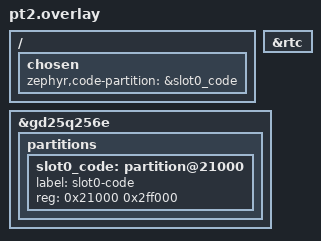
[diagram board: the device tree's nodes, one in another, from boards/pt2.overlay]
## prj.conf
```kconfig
CONFIG_ASSERT=y
CONFIG_BOOT_BANNER=n
CONFIG_CONSOLE=y
CONFIG_CRC=y
CONFIG_DISPLAY=y
CONFIG_FLASH=y
CONFIG_HEAP_MEM_POOL_SIZE=65536
CONFIG_MAIN_STACK_SIZE=2048
CONFIG_MINIMAL_LIBC_RAND=y
# NimBLE's GATT server registers services via libc realloc/malloc
# (ble_gatts_add_svcs). Without a real malloc arena those return NULL and
# ble_svc_gap_init panics. Match the standalone ble app's allocator.
CONFIG_COMMON_LIBC_MALLOC=y
CONFIG_COMMON_LIBC_MALLOC_ARENA_SIZE=16384
CONFIG_NUM_PREEMPT_PRIORITIES=12
CONFIG_PRINTK=y
CONFIG_RTC=y
CONFIG_REBOOT=y
CONFIG_SERIAL=y
CONFIG_THREAD_NAME=y
CONFIG_UART_CONSOLE=y

CONFIG_SYSTEM_WORKQUEUE_STACK_SIZE=4096

# PebbleOS emits concise bring-up markers directly on UART.
CONFIG_LOG=y
CONFIG_LOG_MODE_IMMEDIATE=y

# Keep firmware threads privileged. The custom hooks only alter the app map
# after fw_sandbox_launch() has prepared and armed the sandbox.
CONFIG_ARM_MPU=y
CONFIG_ARM_CUSTOM_SVC_HOOK=y
CONFIG_ARM_CUSTOM_THREAD_RESTORE_HOOK=y
CONFIG_USERSPACE=n
```

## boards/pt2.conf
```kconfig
CONFIG_GPIO=y
CONFIG_SF32LB_JDI=y
CONFIG_WATCHDOG=y

# NimBLE host and the SF32 LCPU controller transport.
CONFIG_USE_SIFLI_HAL=y
CONFIG_USE_SIFLI_HAL_AON=y
CONFIG_USE_SIFLI_HAL_LCPU_PATCH=y
CONFIG_USE_SIFLI_HAL_MAILBOX=y
CONFIG_USE_SIFLI_HAL_SYSTEM_CONFIG=y

# HCPU/LCPU HCI rings live in shared SRAM. The port does not yet install the
# shipping non-cacheable MPU region, so keep the HCPU D-cache disabled to make
# controller IPC coherent.
CONFIG_DCACHE=n
```

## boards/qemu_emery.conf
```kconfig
CONFIG_INPUT=y
CONFIG_FLASH_PAGE_LAYOUT=y
# RTC_TICKS_HZ derives from this; the animation rate-control loop needs ~1ms
# resolution (shipping runs 1024 Hz) or frame cadence oscillates.
CONFIG_SYS_CLOCK_TICKS_PER_SEC=1000
```

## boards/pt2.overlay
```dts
/* SPDX-License-Identifier: Apache-2.0 */

&rtc {
	status = "okay";
};

/* Slot 0 base 0x12020000. pblboot's 28-byte header sits at the base and the
 * firmware body (vector table) begins at slot_base + 0x1000, matching pblboot
 * CONFIG_FIRMWARE_OFFSET=4096. Reserve that 0x1000 header page outside ROM. */
&gd25q256e {
	partitions {
		/delete-node/ partition@10000;

		slot0_code: partition@21000 {
			label = "slot0-code";
			reg = <0x21000 0x2ff000>;
		};
	};
};

/ {
	chosen {
		zephyr,code-partition = &slot0_code;
	};
};
```

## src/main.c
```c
/* SPDX-FileCopyrightText: 2024 Google LLC */
/* SPDX-License-Identifier: Apache-2.0 */

#include <time.h>

#include "FreeRTOS.h"
#include "app_registry.h"
#include "applib/tick_timer_service.h"
#include "applib/ui/animation_private.h"
#include "applib/tick_timer_service_private.h"
#include "ble_comm.h"
#include "button_input.h"
#include "fw_ota_boot.h"
#include "kernel/event_loop.h"
#include "kernel/events.h"
#include "kernel/kernel_applib_state.h"
#include "process_state/app_state/app_state.h"
#include "kernel/pebble_tasks.h"
#include "kernel/util/task_init.h"
#include "launcher_ui.h"
#include "pbl/drivers/task_watchdog.h"
#include "pbl/logging/logging.h"
#include "pbl/services/analytics/analytics.h"
#include "pbl/services/event_service.h"
#include "pbl/services/new_timer/new_timer.h"
#include "pbl/services/new_timer/new_timer_service.h"
#include "pbl/services/regular_timer.h"
#include "pbl/services/system_task.h"
#include "pfs_boot.h"
#include "sandbox_launcher.h"

void board_early_init(void);
void board_init(void);

static TimerID s_probe_timer;

static void prv_watchdog_timer_callback(void *data) {
  (void)data;
  task_watchdog_bit_set(PebbleTask_NewTimers);
}

static RegularTimerInfo s_watchdog_timer = {
    .cb = prv_watchdog_timer_callback,
};

static void prv_timer_dispatched(void *data) {
  (void)data;
  PBL_LOG_ALWAYS("FW_TIMER dispatched");
}

static void prv_timer_fired(void *data) {
  (void)data;
  launcher_task_add_callback(prv_timer_dispatched, NULL);
}

static void prv_tick_handler(struct tm *tick_time, TimeUnits units_changed) {
  (void)units_changed;
  PBL_LOG_ALWAYS("FW_TICK %02d:%02d:%02d", tick_time->tm_hour, tick_time->tm_min,
                 tick_time->tm_sec);
}

// Shipping drives tick_timer_service from a RegularTimer that the port never
// pumps, so the clock and music progress never advanced. Emit PEBBLE_TICK_EVENT
// once a second from a repeating new_timer (which the port does pump); the
// per-task tick_timer_service state turns it into second/minute tick callbacks.
extern time_t rtc_get_time(void);
static TimerID s_tick_timer;

static void prv_second_tick(void *data) {
  (void)data;
  PebbleEvent e = {
    .type = PEBBLE_TICK_EVENT,
    .clock_tick = { .tick_time = rtc_get_time() },
  };
  event_put(&e);
}

static void prv_kernel_main(void *parameter) {
  (void)parameter;
  task_init();

  // Shipping inits the kernel animation state from kernel_ui_init on
  // KernelMain; both engine states allocate their aux state on the heap.
  animation_private_state_init(kernel_applib_get_animation_state());
  animation_private_state_init(app_state_get_animation_state());

  TickTimerServiceState *tick_state = kernel_applib_get_tick_timer_service_state();
  tick_timer_service_state_init(tick_state);
  tick_timer_service_init();
  tick_timer_service_subscribe(SECOND_UNIT, prv_tick_handler);

  s_probe_timer = new_timer_create();
  new_timer_start(s_probe_timer, 1500, prv_timer_fired, NULL, 0);

  s_tick_timer = new_timer_create();
  new_timer_start(s_tick_timer, 1000, prv_second_tick, NULL, TIMER_START_FLAG_REPEATING);

  PBL_LOG_ALWAYS("FW_SERVICES_OK");

  // Buttons: prove the debounce filter, then bring up the real click_recognizer
  // and start sampling the physical GPIOs. Must run on KernelMain so click.c's
  // app_timer callbacks dispatch back on this task via the event loop.
  button_input_selfcheck();
  input_service_init();
  button_zephyr_init();

  // PFS must mount and the app registry must enumerate before board drivers,
  // the watchdog, or analytics run. Bringing those up first (as the un-stub
  // originally did) perturbs the system out of the clean state PFS mounts in
  // and the filesystem fails to mount (apps=0). Keep filesystem-first ordering.
  if (fw_pfs_boot() == 0) {
    PBL_LOG_ALWAYS("FW_PFS_UP");
    fw_app_registry_init();
    // Real shell + notification prefs (shipping: shell_event_loop /
    // services init); load and persist their settings files on PFS.
    extern void shell_prefs_init(void);
    shell_prefs_init();
    extern void alerts_preferences_init(void);
    alerts_preferences_init();
    extern void do_not_disturb_init(void);
    do_not_disturb_init();
    // pin_db must be up before alarm_init: reloading persisted alarms re-adds
    // their timeline pins through alarm_pin_add -> pin_db.
    extern void notification_storage_init(void);
    notification_storage_init();
    extern void pin_db_init(void);
    pin_db_init();
    extern void alarm_init(void);
    alarm_init();
    // Shipping enables the alarm service via the services_normal registry, which
    // the port does not compile; without this s_alarms_enabled stays false and a
    // firing alarm never posts PEBBLE_ALARM_CLOCK_EVENT.
    extern void alarm_service_enable_alarms(bool enable);
    alarm_service_enable_alarms(true);
    extern void fw_alarm_alert_init(void);
    fw_alarm_alert_init();
    extern void fw_pbw_install_init(void);
    fw_pbw_install_init();
    extern void persist_service_init(void);
    persist_service_init();
#if defined(CONFIG_BOARD_QEMU_EMERY)
    extern void fw_qemu_notif_rx_init(void);
    fw_qemu_notif_rx_init();
#endif
  }

  // Board drivers / watchdog / analytics: real Zephyr-backed bring-up, after PFS.
  task_watchdog_init();
  task_watchdog_pause(30);
  regular_timer_add_seconds_callback(&s_watchdog_timer);
  pbl_analytics_init();
  PBL_ANALYTICS_SET_UNSIGNED(uptime_s, 0U);
  board_init();

  // Controller calibration and NimBLE host startup run on dedicated Zephyr
  // threads. Keep this after PFS and board initialization so shared-RAM/radio
  // bring-up cannot perturb the clean state required by the filesystem mount.
  fw_ble_init();

  task_watchdog_mask_set(PebbleTask_KernelMain);
  task_watchdog_resume();
  PBL_LOG_ALWAYS("FW_WATCHDOG_OK");
  PBL_LOG_ALWAYS("FW_ANALYTICS_OK");

  // Stand up the real window stack + launcher menu and run the KernelMain UI
  // event loop. Navigation consumes the button/click-service events wired above
  // (button_zephyr -> event queue -> input_service click_recognizer); SELECT
  // launches the selected app. Replaces the previous auto-launch + bare
  // launcher_main_loop().
  fw_launcher_ui_run();
}

static void prv_log_stubs(void) {
  // ponytail: the port writes Pebble framebuffers directly with Zephyr's JDI
  // display driver. Add the real compositor and kernel-ui service graph here.
  PBL_LOG_ALWAYS("FW_STUB display_compositor");
}

int main(void) {
  PBL_LOG_ALWAYS("FW_BOOT");
  board_early_init();
  fw_boot_select_and_report();
  if (fw_ota_test_injection_requested() &&
      (fw_ota_inject_test_image() != 0)) {
    PBL_LOG_ALWAYS("FW_OTA_TEST_FAILED");
  }
  prv_log_stubs();

  events_init();
  event_service_system_init();
  new_timer_service_init();
  regular_timer_init();
  system_task_init();
  // KernelBackground adds itself to the task-watchdog mask but only feeds its
  // bit while running a callback; this registers the per-second idle feed that
  // keeps the HW watchdog fed while KernelBackground sits idle. Without it the
  // masked-but-unfed bit stalls the whole feed and the SoC resets ~10s in.
  system_task_timer_init();

  TaskParameters_t main_task = {
    .pvTaskCode = prv_kernel_main,
    .pcName = "KernelMain",
    .usStackDepth = 10240 / sizeof(portSTACK_TYPE),
    .uxPriority = tskIDLE_PRIORITY + 3,
  };
  pebble_task_create(PebbleTask_KernelMain, &main_task, NULL);
  return 0;
}
```

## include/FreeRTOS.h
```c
/* SPDX-License-Identifier: Apache-2.0 */
#pragma once

#include <stdint.h>

#include <zephyr/kernel.h>

typedef int BaseType_t;
#define portBASE_TYPE int
typedef unsigned int UBaseType_t;
typedef void *QueueHandle_t;
typedef void *QueueSetHandle_t;
typedef void *QueueSetMemberHandle_t;
typedef void *SemaphoreHandle_t;
typedef void *TaskHandle_t;
typedef uint32_t TickType_t;
typedef uint32_t StackType_t;
typedef StackType_t portSTACK_TYPE;

#define pdFALSE 0
#define pdTRUE 1
#define pdFAIL 0
#define pdPASS 1

#define configMAX_PRIORITIES 8
#define configTICK_RATE_HZ CONFIG_SYS_CLOCK_TICKS_PER_SEC
#define portMAX_DELAY UINT32_MAX
#define portPRIVILEGE_BIT 0
#define tskIDLE_PRIORITY 0

typedef struct {
  TaskHandle_t xHandle;
  uint32_t ulRunTimeCounter;
} TaskStatus_t;

typedef enum {
  eRunning,
  eReady,
  eBlocked,
  eSuspended,
  eDeleted,
  eInvalid,
} eTaskState;

typedef struct xMEMORY_REGION {
  void *pvBaseAddress;
  uint32_t ulLengthInBytes;
  uint32_t ulParameters;
} MemoryRegion_t;

#define portNUM_CONFIGURABLE_REGIONS 4

typedef void (*TaskFunction_t)(void *);

typedef struct xTASK_PARAMETERS {
  TaskFunction_t pvTaskCode;
  const char *pcName;
  uint32_t usStackDepth;
  UBaseType_t uxPriority;
  StackType_t *puxStackBuffer;
  MemoryRegion_t xRegions[portNUM_CONFIGURABLE_REGIONS];
  void *pvParameters;
} TaskParameters_t;
```

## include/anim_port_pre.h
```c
/* SPDX-License-Identifier: Apache-2.0 */
#pragma once

// Force-included ahead of the real applib animation engine + animation service
// TUs. Supplies the Zephyr sign_extend dance, FreeRTOS-style critical sections
// (single-pump port: IRQ lock), the legacy2 header's expected types, and the
// scheduler-dump serial sink.
#include "fw_zephyr_pre.h"
#include "port_crit.h"

#include "applib/app_timer.h"

typedef enum AppTaskCtxIdx {
  AppTaskCtxIdxLauncher = 0,
  AppTaskCtxIdxApp,
  AppTaskCtxIdxCount,
} AppTaskCtxIdx;

#include <zephyr/sys/printk.h>
#define dbgserial_putstr_fmt(buffer, size, fmt, ...) \
  do { snprintk((buffer), (size), fmt, ##__VA_ARGS__); printk("%s\n", (buffer)); } while (0)

#include "process_management/process_manager.h"
```

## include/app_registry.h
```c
/* SPDX-License-Identifier: Apache-2.0 */
#pragma once

#include <stdbool.h>
#include <stddef.h>
#include <stdint.h>

#include "process_management/app_install_types.h"
#include "process_management/pebble_process_md.h"
#include "pbl/util/uuid.h"

#define FW_APP_NAME_SIZE 96

typedef struct {
  AppInstallId install_id;
  Uuid uuid;
  uint32_t info_flags;
  bool installed;
  char name[FW_APP_NAME_SIZE + 1];
  // Non-NULL for a privileged built-in system app: its real PebbleProcessMd.
  // The launcher hands this to fw_system_app_launch() on SELECT. NULL entries
  // fall back to the sandboxed PBW launch.
  const PebbleProcessMd *md;
} FwAppRegistryEntry;

void fw_app_registry_init(void);
size_t fw_app_registry_count(void);
const FwAppRegistryEntry *fw_app_registry_get(size_t index);
const FwAppRegistryEntry *fw_launcher_pick_app(void);
const FwAppRegistryEntry *fw_app_registry_find_by_id(AppInstallId install_id);
void fw_app_registry_reload(void);
```

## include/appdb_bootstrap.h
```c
/* SPDX-License-Identifier: Apache-2.0 */
#pragma once

#include "process_management/app_install_types.h"

//! Install the port's bundled test PBW as a normal PFS/AppDB application.
//! Returns INSTALL_ID_INVALID on failure.
AppInstallId fw_appdb_install_test_app(void);
```

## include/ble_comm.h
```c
/* SPDX-License-Identifier: Apache-2.0 */
#pragma once

// Starts controller and NimBLE-host initialization on a dedicated thread.
// The caller must invoke this only after PFS and board initialization.
void fw_ble_init(void);
```

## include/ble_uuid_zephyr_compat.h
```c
/* SPDX-License-Identifier: Apache-2.0 */
#pragma once

// Zephyr exports a four-argument hex2bin. NimBLE has a private, static
// three-argument helper with the same name. Rename only NimBLE's helper.
#include "nimble_zephyr_compat.h"

#define hex2bin nimble_ble_uuid_hex2bin
```

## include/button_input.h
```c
/* SPDX-License-Identifier: Apache-2.0 */
//! Obelix (pt2) button bring-up under Zephyr.
//!
//! Bottom half: reads the four physical button GPIOs, runs the shipping
//! debounce filter, and emits real PebbleEvents (PEBBLE_BUTTON_DOWN/UP).
//! Top half: feeds those events into the real PebbleOS click_recognizer.
#pragma once

#include <stdint.h>

#include "kernel/events.h"
#include <pbl/drivers/button_id.h>

//! Number of stable 2ms samples a button must hold before its state flips.
//! 20 samples * 2ms = 40ms, identical to the shipping sf32lb52 driver.
#define BUTTON_NUM_DEBOUNCE_SAMPLES 20

//! Pure debounce filter state (one per button set). Host-testable: no I/O.
typedef struct {
  uint32_t timers[NUM_BUTTONS];
  uint32_t debounced_state;  //!< bitset, bit i == BUTTON_ID_i currently pressed
} ButtonDebouncer;

//! Advance the debounce filter one 2ms sample.
//! @param raw_state bitset of raw (already active-level-adjusted) pressed bits
//! @return bitset of buttons whose debounced state flipped this step
uint32_t button_debounce_step(ButtonDebouncer *d, uint32_t raw_state);

//! Board backend: prepare the raw button source. Returns 0 on success.
int button_raw_init(void);

//! Board backend: current raw pressed-bitset (active-level adjusted).
uint32_t button_raw_read(void);

//! Bring up the raw button source and start the 2ms sampling timer.
void button_zephyr_init(void);

//! Runtime self-check of the debounce filter + event mapping. Asserts on
//! failure, logs a marker on success. Safe to call once at boot.
void button_input_selfcheck(void);

//! Initialise the click_recognizer demo (owns a ClickManager, subscribes
//! single/repeat/long/multi/raw handlers that log over UART).
void input_service_init(void);

//! Feed one debounced button event into the click_recognizer. Called from the
//! KernelMain event loop. Logs "BTN <id> DOWN/UP".
void input_service_handle_button_event(PebbleEvent *e);
```

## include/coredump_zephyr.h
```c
/* SPDX-License-Identifier: Apache-2.0 */

#pragma once

#include <stdbool.h>

#include <zephyr/arch/cpu.h>
#include <zephyr/toolchain.h>

//! Emit an unread PebbleOS coredump as hex-framed UART records.
//! Returns true when any valid coredump is present, including an already-read one.
bool coredump_zephyr_emit_uart(void);

//! Deliberately generate a CPU fault when PEBBLE_COREDUMP_TEST_FAULT is enabled.
void coredump_zephyr_test_fault(void);

//! Capture the supplied Zephyr fatal frame with the PebbleOS writer and reset.
FUNC_NORETURN void coredump_zephyr_capture_fatal(
    unsigned int reason, const struct arch_esf *esf);
```

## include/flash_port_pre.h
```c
/* SPDX-License-Identifier: Apache-2.0 */
#pragma once

// Force-included (via CMake -include) ahead of the shipping QSPI flash sources
// (src/fw/drivers/flash/gd25q256e.c, src/fw/drivers/sf32lb52/qspi.c) and the
// port's qspi_board.c, to reproduce the include environment those files get in
// the shipping build.

// 1. Zephyr's sys/util.h and Pebble's pbl/util/math.h both declare sign_extend()
//    with different signatures. Pull Zephyr in with it renamed so the Pebble
//    declaration wins (mirrors fw_zephyr_pre.h).
#define sign_extend zephyr_sign_extend
#include <zephyr/kernel.h>
#undef sign_extend

// 2. Include the SiFli HAL umbrella FIRST. register.h re-enters bf0_hal.h, which
//    pulls the per-module headers (adc/i2c/mpi/...) that reference
//    DMA_HandleTypeDef. If bf0_hal_dma.h is included first instead (as happens
//    via pbl/drivers/qspi_definitions.h), that cascade runs before
//    DMA_HandleTypeDef is defined. Including bf0_hal.h up front makes its include
//    guard absorb the re-entry so every module header resolves in order.
#include "bf0_hal.h"

// 3. The shipping flash driver references the board's QSPI objects, declared in
//    board_obelix.h in shipping. The port uses an empty board.h shadow, so
//    declare them here. Definitions live in qspi_board.c.
#include <pbl/drivers/flash/qspi_flash.h>
extern QSPIPort *const QSPI;
extern QSPIFlash *const QSPI_FLASH;

// 4. FreeRTOS-style critical sections used by qspi.c, mapped onto Zephyr's IRQ
//    lock.
#include "port_crit.h"
```

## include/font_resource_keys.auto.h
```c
/* SPDX-License-Identifier: Apache-2.0 */
#pragma once

// Port shadow of the generated font-key table (fw/include is first on the
// include path). fonts_get_system_font() (watchface_sandboxed/port.c) matches
// these keys to the real embedded GOTHIC faces; unembedded keys (e.g. LECO) fall
// back to GOTHIC_14.

#define FONT_KEY_GOTHIC_14 "RESOURCE_ID_GOTHIC_14"
#define FONT_KEY_GOTHIC_14_BOLD "RESOURCE_ID_GOTHIC_14_BOLD"
#define FONT_KEY_GOTHIC_18 "RESOURCE_ID_GOTHIC_18"
#define FONT_KEY_GOTHIC_18_BOLD "RESOURCE_ID_GOTHIC_18_BOLD"
#define FONT_KEY_GOTHIC_24 "RESOURCE_ID_GOTHIC_24"
#define FONT_KEY_GOTHIC_24_BOLD "RESOURCE_ID_GOTHIC_24_BOLD"
#define FONT_KEY_GOTHIC_28 "RESOURCE_ID_GOTHIC_28"
#define FONT_KEY_GOTHIC_28_BOLD "RESOURCE_ID_GOTHIC_28_BOLD"
#define FONT_KEY_GOTHIC_36 "RESOURCE_ID_GOTHIC_36"
#define FONT_KEY_GOTHIC_36_BOLD "RESOURCE_ID_GOTHIC_36_BOLD"
#define FONT_KEY_BITHAM_34_MEDIUM_NUMBERS "RESOURCE_ID_BITHAM_34_MEDIUM_NUMBERS"
#define FONT_KEY_GOTHIC_36 "RESOURCE_ID_GOTHIC_36"
#define FONT_KEY_GOTHIC_36_BOLD "RESOURCE_ID_GOTHIC_36_BOLD"
#define FONT_KEY_LECO_20_BOLD_NUMBERS "RESOURCE_ID_LECO_20_BOLD_NUMBERS"
#define FONT_KEY_LECO_26_BOLD_NUMBERS_AM_PM "RESOURCE_ID_LECO_26_BOLD_NUMBERS_AM_PM"
#define FONT_KEY_LECO_38_BOLD_NUMBERS "RESOURCE_ID_LECO_38_BOLD_NUMBERS"
```

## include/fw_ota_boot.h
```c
/* SPDX-License-Identifier: Apache-2.0 */

#pragma once

#include <stdbool.h>
#include <stddef.h>
#include <stdint.h>

typedef enum FwBootSelection {
  FwBootSelectionNone = 0,
  FwBootSelectionNormalSlot0,
  FwBootSelectionNormalSlot1,
  FwBootSelectionPrf,
} FwBootSelection;

typedef enum FwOtaImageType {
  FwOtaImageFirmware = 0,
  FwOtaImageRecovery,
} FwOtaImageType;

//! Validate both normal slots, choose the higher-priority valid image, and
//! fall back to the validated PRF region when neither normal slot is valid.
FwBootSelection fw_boot_select(void);

//! Run the scaffold boot selection and emit FW_BOOT_SLOT normal|prf.
FwBootSelection fw_boot_select_and_report(void);

//! Start streaming a pblboot-format image into firmware slot1. A zero append
//! offset erases the complete 4 KiB-rounded image span before any bytes are
//! written. A non-zero offset is accepted only for a live interrupted transfer.
int fw_ota_slot_begin(uint32_t image_size, uint32_t append_offset);

//! Append bytes at the exact next image offset. The pblboot header is retained
//! in RAM until install so an interrupted transfer cannot become bootable.
int fw_ota_slot_write(uint32_t offset, const uint8_t *data, uint32_t length);

//! Validate the complete streamed image and its in-header IEEE CRC. This leaves
//! the slot header erased; fw_ota_slot_install() is the bootable commit point.
int fw_ota_slot_finish(void);

//! Commit the retained header verbatim, then validate the bootable slot from
//! flash. Returns only after all blocking QSPI writes and readback complete.
int fw_ota_slot_install(void);

//! Abandon the current receive. If the header was already installed, erase its
//! 4 KiB subsector so pblboot cannot select the abandoned image.
void fw_ota_slot_abort(void);

//! Receive a complete pblboot-format firmware blob using the streaming slot1
//! path. This compatibility wrapper is not used by BLE PutBytes.
int fw_ota_receive_image(const uint8_t *image, size_t image_size,
                         FwOtaImageType image_type);

//! Locally inject a small CRC-valid, deliberately non-executable test image.
//! This exists to exercise receive/validation/commit without BLE transport.
int fw_ota_inject_test_image(void);

//! Runtime predicate kept across translation units so the default-off build
//! retains the callable OTA receive path in the linked image.
bool fw_ota_test_injection_requested(void);
```

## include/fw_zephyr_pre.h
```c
/* SPDX-License-Identifier: Apache-2.0 */
#pragma once

// Force-included (via CMake -include) ahead of a real PebbleOS app source that
// pulls BOTH Zephyr (through FreeRTOS.h) and the Pebble graphics/math headers.
// Zephyr's sys/util.h and Pebble's pbl/util/math.h both declare sign_extend()
// with different signatures; pre-include Zephyr with sign_extend renamed so the
// Pebble declaration is the one that wins for the app code. Mirrors the dance in
// launcher_ui.c / sandbox_graphics_state.h.
#define sign_extend zephyr_sign_extend
#include <zephyr/kernel.h>
#undef sign_extend
```
